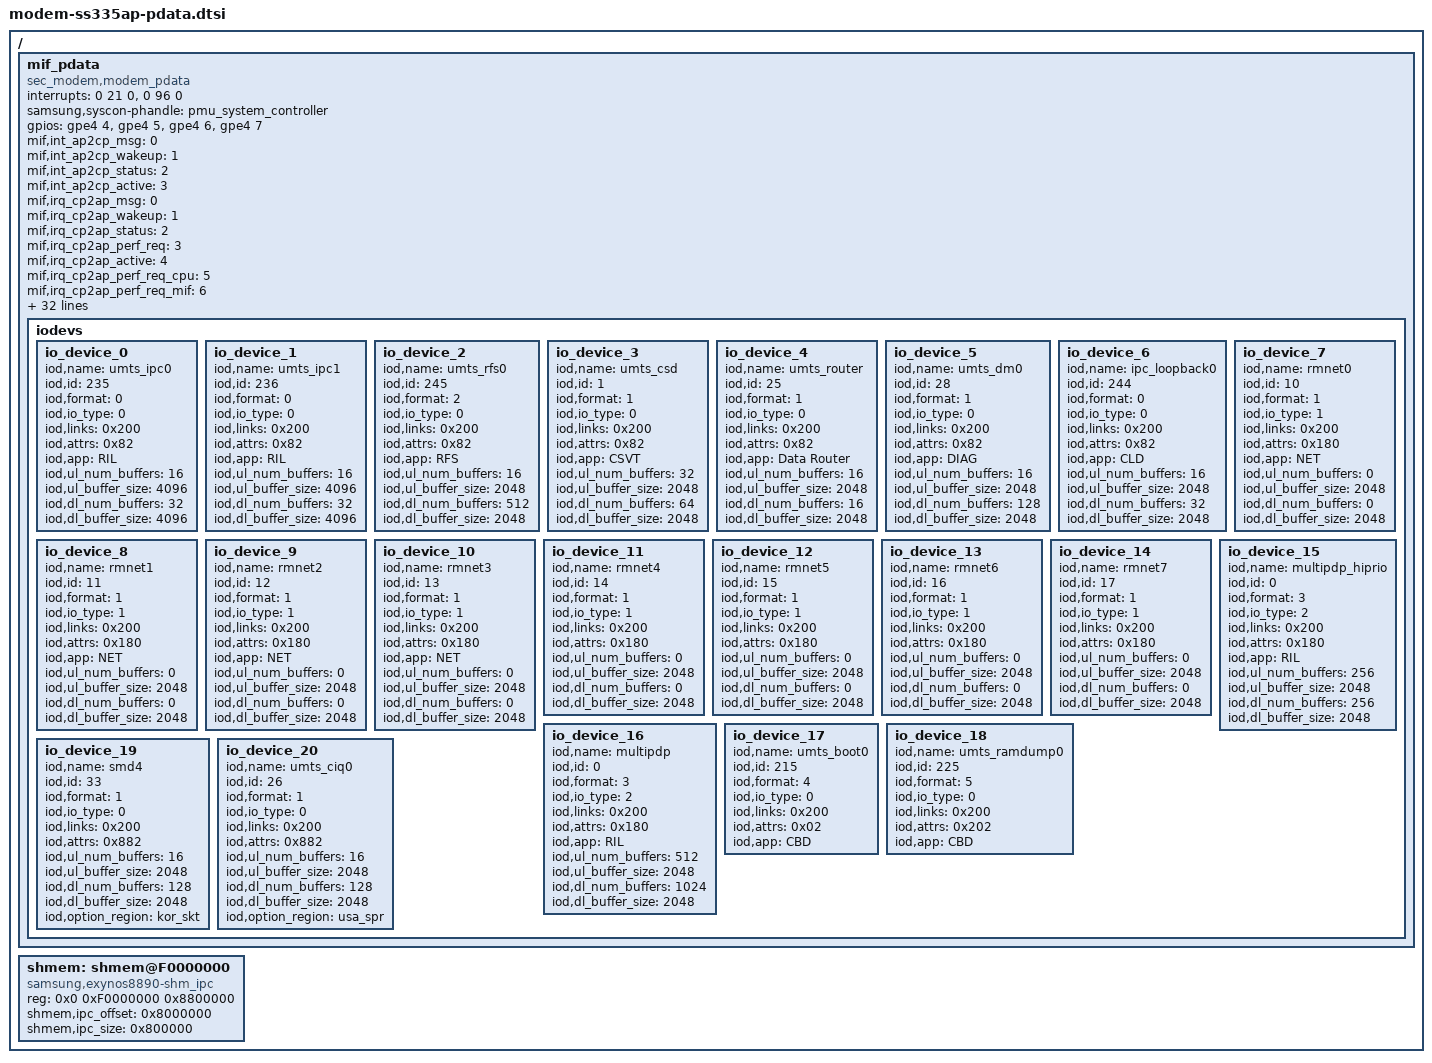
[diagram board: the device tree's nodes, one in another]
/*
 * SAMSUNG UNIVERSAL8890 board device tree source
 *
 * Copyright (c) 2014 Samsung Electronics Co., Ltd.
 *             http://www.samsung.com
 *
 * This program is free software; you can redistribute it and/or modify
 * it under the terms of the GNU General Public License version 2 as
 * published by the Free Software Foundation.
*/

/ {
	/* modem_interface_driver: Samsung Electronics Jungfrau */
	mif_pdata {
		compatible = "sec_modem,modem_pdata";
		status = "okay";
		interrupts = <0 21 0>, <0 96 0>;
		samsung,syscon-phandle = <&pmu_system_controller>;
		gpios = <&gpe4 4 0>, <&gpe4 5 0>, <&gpe4 6 0>, <&gpe4 7 0>;

		mif,int_ap2cp_msg = <0>;
		mif,int_ap2cp_wakeup = <1>;
		mif,int_ap2cp_status = <2>;
		mif,int_ap2cp_active = <3>;

		mif,irq_cp2ap_msg = <0>;
		mif,irq_cp2ap_wakeup = <1>;
		mif,irq_cp2ap_status = <2>;
		mif,irq_cp2ap_perf_req = <3>;
		mif,irq_cp2ap_active = <4>;
		mif,irq_cp2ap_perf_req_cpu = <5>;
		mif,irq_cp2ap_perf_req_mif = <6>;
		mif,irq_cp2ap_perf_req_int = <7>;
		mif,irq_cp2ap_wakelock = <8>;
		mif,irq_cp2ap_pcie_l1ss_disable = <9>;

		mbx_ap2cp_msg = <0>;
		mbx_cp2ap_msg = <1>;
		mbx_ap2cp_wakeup = <2>;
		mbx_cp2ap_wakeup = <3>;
		mbx_ap2cp_status = <4>;
		mbx_cp2ap_status = <5>;
		mbx_ap2cp_active = <6>;
		mbx_cp2ap_dvfsreq = <7>;
		mbx_cp2ap_wakelock = <8>;
		mbx_cp2ap_active = <9>;
		mbx_cp2ap_dvfsreq_cpu = <10>;
		mbx_cp2ap_dvfsreq_mif = <11>;
		mbx_cp2ap_dvfsreq_int = <12>;
		mbx_ap2cp_mif_value = <13>;
		mbx_ap2cp_sec = <14>;
		mbx_ap2cp_usec = <15>;
		mbx_cp2ap_pcie_l1ss_disable = <17>;
		mbx_ap2cp_et_dac_cal = <32>;
		mbx_ap2cp_info_value = <33>;
		mbx_ap2cp_lock_value = <39>;

		mif,name = "ss335ap";
		mif,modem_net = <0>;		/* UMTS_NETWORK */
		mif,modem_type = <10>;		/* SEC_SS310AP */
		mif,use_handover = <0>;		/* not used */
		mif,ipc_version = <50>;		/* SIPC 5.0 */
		mif,link_types = <0x200>;	/* LINKDEV_SHMEM */
		mif,link_name = "shmem";
		mif,link_attrs = <0x7C9>;	/* XMIT_BTDLR(0x400) | DUMP_ALIGNED (0x200) | BOOT_ALIGNED (0x100) | MEM_DUMP (0x80) | MEM_BOOT (0x40) | DPRAM_MAGIC (0x08) | SBD_IPC (0x01) */
		mif,num_iodevs = <21>;
		iodevs {
			io_device_0 {
				iod,name = "umts_ipc0";
				iod,id = <235>;
				iod,format = <0>;		/* IPC_FMT */
				iod,io_type = <0>;		/* IODEV_MISC */
				iod,links = <0x200>;		/* LINKDEV_SHMEM */
				iod,attrs = <0x82>;		/* ATTR_SBD_IPC | ATTR_SIPC5 */
				iod,app = "RIL";
				iod,ul_num_buffers = <16>;
				iod,ul_buffer_size = <4096>;
				iod,dl_num_buffers = <32>;
				iod,dl_buffer_size = <4096>;
			};
			io_device_1 {
				iod,name = "umts_ipc1";
				iod,id = <236>;
				iod,format = <0>;		/* IPC_FMT */
				iod,io_type = <0>;		/* IODEV_MISC */
				iod,links = <0x200>;		/* LINKDEV_SHMEM */
				iod,attrs = <0x82>;		/* ATTR_SBD_IPC | ATTR_SIPC5 */
				iod,app = "RIL";
				iod,ul_num_buffers = <16>;
				iod,ul_buffer_size = <4096>;
				iod,dl_num_buffers = <32>;
				iod,dl_buffer_size = <4096>;
			};
			io_device_2 {
				iod,name = "umts_rfs0";
				iod,id = <245>;
				iod,format = <2>;		/* IPC_RFS */
				iod,io_type = <0>;
				iod,links = <0x200>;
				iod,attrs = <0x82>;
				iod,app = "RFS";
				iod,ul_num_buffers = <16>;
				iod,ul_buffer_size = <2048>;
				iod,dl_num_buffers = <512>;
				iod,dl_buffer_size = <2048>;
			};
			io_device_3 {
				iod,name = "umts_csd";
				iod,id = <1>;
				iod,format = <1>;
				iod,io_type = <0>;
				iod,links = <0x200>;
				iod,attrs = <0x82>;
				iod,app = "CSVT";
				iod,ul_num_buffers = <32>;
				iod,ul_buffer_size = <2048>;
				iod,dl_num_buffers = <64>;
				iod,dl_buffer_size = <2048>;
			};
			io_device_4 {
				iod,name = "umts_router";
				iod,id = <25>;
				iod,format = <1>;
				iod,io_type = <0>;
				iod,links = <0x200>;
				iod,attrs = <0x82>;
				iod,app = "Data Router";
				iod,ul_num_buffers = <16>;
				iod,ul_buffer_size = <2048>;
				iod,dl_num_buffers = <16>;
				iod,dl_buffer_size = <2048>;
			};
			io_device_5 {
				iod,name = "umts_dm0";
				iod,id = <28>;
				iod,format = <1>;
				iod,io_type = <0>;
				iod,links = <0x200>;
				iod,attrs = <0x82>;
				iod,app = "DIAG";
				iod,ul_num_buffers = <16>;
				iod,ul_buffer_size = <2048>;
				iod,dl_num_buffers = <128>;
				iod,dl_buffer_size = <2048>;
			};
			io_device_6 {
				iod,name = "ipc_loopback0";
				iod,id = <244>;
				iod,format = <0>;
				iod,io_type = <0>;
				iod,links = <0x200>;
				iod,attrs = <0x82>;
				iod,app = "CLD";
				iod,ul_num_buffers = <16>;
				iod,ul_buffer_size = <2048>;
				iod,dl_num_buffers = <32>;
				iod,dl_buffer_size = <2048>;
			};
			io_device_7 {
				iod,name = "rmnet0";
				iod,id = <10>;
				iod,format = <1>;
				iod,io_type = <1>;		/* IODEV_NET */
				iod,links = <0x200>;
				iod,attrs = <0x180>;		/* ATTR_SBD_IPC (0x80) | ATTR_NO_LINK_HDR(0x100) */
				iod,app = "NET";
				iod,ul_num_buffers = <0>;
				iod,ul_buffer_size = <2048>;
				iod,dl_num_buffers = <0>;
				iod,dl_buffer_size = <2048>;
			};
			io_device_8 {
				iod,name = "rmnet1";
				iod,id = <11>;
				iod,format = <1>;
				iod,io_type = <1>;
				iod,links = <0x200>;
				iod,attrs = <0x180>;
				iod,app = "NET";
				iod,ul_num_buffers = <0>;
				iod,ul_buffer_size = <2048>;
				iod,dl_num_buffers = <0>;
				iod,dl_buffer_size = <2048>;
			};
			io_device_9 {
				iod,name = "rmnet2";
				iod,id = <12>;
				iod,format = <1>;
				iod,io_type = <1>;
				iod,links = <0x200>;
				iod,attrs = <0x180>;
				iod,app = "NET";
				iod,ul_num_buffers = <0>;
				iod,ul_buffer_size = <2048>;
				iod,dl_num_buffers = <0>;
				iod,dl_buffer_size = <2048>;
			};
			io_device_10 {
				iod,name = "rmnet3";
				iod,id = <13>;
				iod,format = <1>;
				iod,io_type = <1>;
				iod,links = <0x200>;
				iod,attrs = <0x180>;
				iod,app = "NET";
				iod,ul_num_buffers = <0>;
				iod,ul_buffer_size = <2048>;
				iod,dl_num_buffers = <0>;
				iod,dl_buffer_size = <2048>;
			};
			io_device_11 {
				iod,name = "rmnet4";
				iod,id = <14>;
				iod,format = <1>;
				iod,io_type = <1>;
				iod,links = <0x200>;
				iod,attrs = <0x180>;	/* ATTR_NO_LINK_HDR(0x100) | ATTR_SBD_IPC (0x80) */
				iod,ul_num_buffers = <0>;
				iod,ul_buffer_size = <2048>;
				iod,dl_num_buffers = <0>;
				iod,dl_buffer_size = <2048>;
			};
			io_device_12 {
				iod,name = "rmnet5";
				iod,id = <15>;
				iod,format = <1>;
				iod,io_type = <1>;
				iod,links = <0x200>;
				iod,attrs = <0x180>;
				iod,ul_num_buffers = <0>;
				iod,ul_buffer_size = <2048>;
				iod,dl_num_buffers = <0>;
				iod,dl_buffer_size = <2048>;
			};
			io_device_13 {
				iod,name = "rmnet6";
				iod,id = <16>;
				iod,format = <1>;
				iod,io_type = <1>;
				iod,links = <0x200>;
				iod,attrs = <0x180>;
				iod,ul_num_buffers = <0>;
				iod,ul_buffer_size = <2048>;
				iod,dl_num_buffers = <0>;
				iod,dl_buffer_size = <2048>;
			};
			io_device_14 {
				iod,name = "rmnet7";
				iod,id = <17>;
				iod,format = <1>;
				iod,io_type = <1>;
				iod,links = <0x200>;
				iod,attrs = <0x180>;
				iod,ul_num_buffers = <0>;
				iod,ul_buffer_size = <2048>;
				iod,dl_num_buffers = <0>;
				iod,dl_buffer_size = <2048>;
			};
			io_device_15 {
				iod,name = "multipdp_hiprio";
				iod,id = <0>;
				iod,format = <3>;		/* IPC_MULTI_RAW */
				iod,io_type = <2>;		/* IODEV_DUMMY */
				iod,links = <0x200>;
				iod,attrs = <0x180>;
				iod,app = "RIL";
				iod,ul_num_buffers = <256>;
				iod,ul_buffer_size = <2048>;
				iod,dl_num_buffers = <256>;
				iod,dl_buffer_size = <2048>;
			};
			io_device_16 {
				iod,name = "multipdp";
				iod,id = <0>;
				iod,format = <3>;		/* IPC_MULTI_RAW */
				iod,io_type = <2>;		/* IODEV_DUMMY */
				iod,links = <0x200>;
				iod,attrs = <0x180>;
				iod,app = "RIL";
				iod,ul_num_buffers = <512>;
				iod,ul_buffer_size = <2048>;
				iod,dl_num_buffers = <1024>;
				iod,dl_buffer_size = <2048>;
			};
			io_device_17 {
				iod,name = "umts_boot0";
				iod,id = <215>;
				iod,format = <4>;		/* IPC_BOOT */
				iod,io_type = <0>;
				iod,links = <0x200>;
				iod,attrs = <0x02>;
				iod,app = "CBD";
			};
			io_device_18 {
				iod,name = "umts_ramdump0";
				iod,id = <225>;
				iod,format = <5>;		/* IPC_DUMP */
				iod,io_type = <0>;
				iod,links = <0x200>;
				iod,attrs = <0x202>;		/* ATTR_NO_CHECK_MAXQ | ATTR_SIPC5 */
				iod,app = "CBD";
			};
			io_device_19 {
				iod,name = "smd4";
				iod,id = <33>;
				iod,format = <1>;
				iod,io_type = <0>;
				iod,links = <0x200>;
				iod,attrs = <0x882>;
				iod,ul_num_buffers = <16>;
				iod,ul_buffer_size = <2048>;
				iod,dl_num_buffers = <128>;
				iod,dl_buffer_size = <2048>;
				iod,option_region = "kor_skt";
			};
			io_device_20 {
				iod,name = "umts_ciq0";
				iod,id = <26>;
				iod,format = <1>;
				iod,io_type = <0>;
				iod,links = <0x200>;
				iod,attrs = <0x882>;
				iod,ul_num_buffers = <16>;
				iod,ul_buffer_size = <2048>;
				iod,dl_num_buffers = <128>;
				iod,dl_buffer_size = <2048>;
				iod,option_region = "usa_spr";
			};
		}; /* end of iodevs */
	}; /* end of mif_pdata */

	shmem: shmem@F0000000 {
		compatible = "samsung,exynos8890-shm_ipc";

		reg = <0x0 0xF0000000 0x8800000>;

		shmem,ipc_offset = <0x8000000>;
		shmem,ipc_size = <0x800000>;
	};
};
